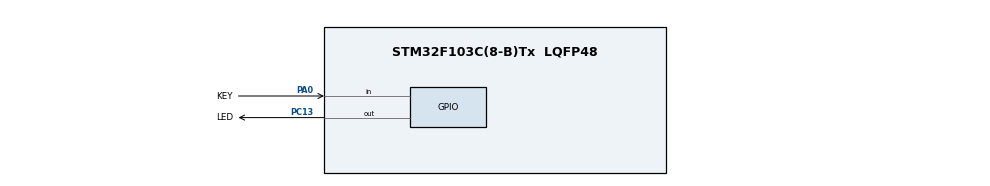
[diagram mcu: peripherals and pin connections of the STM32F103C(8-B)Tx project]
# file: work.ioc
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Mcu.Family=STM32F1
Mcu.Name=STM32F103C(8-B)Tx
Mcu.Package=LQFP48
NVIC.PriorityGroup=NVIC_PRIORITYGROUP_4
PA0-WKUP.GPIO_Label=KEY
PA0-WKUP.GPIO_PuPd=GPIO_PULLUP
PA0-WKUP.Signal=GPIO_Input
PA13.Mode=Serial_Wire
PA13.Signal=SYS_JTMS-SWDIO
PA14.Mode=Serial_Wire
PA14.Signal=SYS_JTCK-SWCLK
PC13-TAMPER-RTC.GPIO_Label=LED
PC13-TAMPER-RTC.GPIO_PuPd=GPIO_PULLUP
PC13-TAMPER-RTC.Signal=GPIO_Output
ProjectManager.HeapSize=0x200
ProjectManager.StackSize=0x400
ProjectManager.TargetToolchain=STM32CubeIDE
RCC.APB1Freq_Value=8000000
RCC.APB2Freq_Value=8000000
board=custom

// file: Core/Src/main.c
/* USER CODE BEGIN Header */
/**
  ******************************************************************************
  * @file           : main.c
  * @brief          : Main program body
  ******************************************************************************
  * @attention
  *
  * Copyright (c) 2026 STMicroelectronics.
  * All rights reserved.
  *
  * This software is licensed under terms that can be found in the LICENSE file
  * in the root directory of this software component.
  * If no LICENSE file comes with this software, it is provided AS-IS.
  *
  ******************************************************************************
  */
/* USER CODE END Header */

#include "main.h"

/* USER CODE BEGIN PD */

/* 自定义引脚宏定义 */
#define LED_Pin     GPIO_PIN_13
#define LED_Port    GPIOC
#define KEY_Pin     GPIO_PIN_0
#define KEY_Port    GPIOA

/* 简化操作宏 */
#define LED_ON()    HAL_GPIO_WritePin(LED_Port, LED_Pin, GPIO_PIN_RESET)   /* 低电平点亮 */
#define LED_OFF()   HAL_GPIO_WritePin(LED_Port, LED_Pin, GPIO_PIN_SET)     /* 高电平熄灭 */
#define LED_TOGGLE() HAL_GPIO_TogglePin(LED_Port, LED_Pin)
#define KEY_PRESSED() (HAL_GPIO_ReadPin(KEY_Port, KEY_Pin) == GPIO_PIN_RESET)  /* 按键按下=低电平 */

/* USER CODE END PD */

void SystemClock_Config(void);
static void MX_GPIO_Init(void);
static uint8_t Key_Scan(void);   /* 按键扫描函数声明 */

int main(void)
{

    /* MCU Configuration--------------------------------------------------------*/
    /* Reset of all peripherals, Initializes the Flash interface and the Systick. */
    HAL_Init();

    /* Configure the system clock */
    SystemClock_Config();

    /* Initialize all configured peripherals */
    MX_GPIO_Init();

    /* Infinite loop */
    /* USER CODE BEGIN WHILE */
    while (1)
    {
        /* 最简单的按键检测：按下时 LED 亮，松开时 LED 灭 */
        if (HAL_GPIO_ReadPin(GPIOA, GPIO_PIN_0) == GPIO_PIN_RESET)  // 按键按下
        {
            HAL_GPIO_WritePin(GPIOC, GPIO_PIN_13, GPIO_PIN_RESET);  // LED 亮
        }
        else
        {
            HAL_GPIO_WritePin(GPIOC, GPIO_PIN_13, GPIO_PIN_SET);    // LED 灭
        }
    }
    /* USER CODE END 3 */
}

void SystemClock_Config(void)
{
    RCC_OscInitTypeDef RCC_OscInitStruct = {0};
    RCC_ClkInitTypeDef RCC_ClkInitStruct = {0};

    /* 配置 HSI 作为系统时钟（不需要外部晶振）*/
    RCC_OscInitStruct.OscillatorType = RCC_OSCILLATORTYPE_HSI;
    RCC_OscInitStruct.HSIState = RCC_HSI_ON;
    RCC_OscInitStruct.HSICalibrationValue = RCC_HSICALIBRATION_DEFAULT;
    RCC_OscInitStruct.PLL.PLLState = RCC_PLL_NONE;
    if (HAL_RCC_OscConfig(&RCC_OscInitStruct) != HAL_OK)
    {
        Error_Handler();
    }

    /* 配置时钟分频 */
    RCC_ClkInitStruct.ClockType = RCC_CLOCKTYPE_HCLK | RCC_CLOCKTYPE_SYSCLK
                                  | RCC_CLOCKTYPE_PCLK1 | RCC_CLOCKTYPE_PCLK2;
    RCC_ClkInitStruct.SYSCLKSource = RCC_SYSCLKSOURCE_HSI;
    RCC_ClkInitStruct.AHBCLKDivider = RCC_SYSCLK_DIV1;
    RCC_ClkInitStruct.APB1CLKDivider = RCC_HCLK_DIV1;
    RCC_ClkInitStruct.APB2CLKDivider = RCC_HCLK_DIV1;

    if (HAL_RCC_ClockConfig(&RCC_ClkInitStruct, FLASH_LATENCY_0) != HAL_OK)
    {
        Error_Handler();
    }
}

static void MX_GPIO_Init(void)
{
    GPIO_InitTypeDef GPIO_InitStruct = {0};

    /* GPIO Ports Clock Enable */
    __HAL_RCC_GPIOC_CLK_ENABLE();   /* PC 端口时钟 */
    __HAL_RCC_GPIOA_CLK_ENABLE();   /* PA 端口时钟 */

    /* 设置 LED(PC13) 初始电平：高电平（LED 熄灭）*/
    HAL_GPIO_WritePin(LED_Port, LED_Pin, GPIO_PIN_SET);

    /* 配置 LED 引脚：PC13 推挽输出 */
    GPIO_InitStruct.Pin = LED_Pin;
    GPIO_InitStruct.Mode = GPIO_MODE_OUTPUT_PP;
    GPIO_InitStruct.Pull = GPIO_NOPULL;       /* 输出模式不需要上拉/下拉 */
    GPIO_InitStruct.Speed = GPIO_SPEED_FREQ_LOW;
    HAL_GPIO_Init(LED_Port, &GPIO_InitStruct);

    /* 配置 KEY 引脚：PA0 上拉输入 */
    GPIO_InitStruct.Pin = KEY_Pin;
    GPIO_InitStruct.Mode = GPIO_MODE_INPUT;
    GPIO_InitStruct.Pull = GPIO_PULLUP;       /* 上拉输入，默认高电平 */
    HAL_GPIO_Init(KEY_Port, &GPIO_InitStruct);

}

/**
  * @brief  带状态机消抖的按键扫描函数
  * @retval 1: 有效按键按下  0: 无按键或抖动
  */
static uint8_t Key_Scan(void)
{
    static uint8_t key_state = 0;      /* 0:等待按键, 1:消抖确认, 2:等待释放 */
    static uint32_t debounce_time = 0;

    switch(key_state)
    {
        case 0:  /* 等待按键按下 */
            if(KEY_PRESSED())
            {
                key_state = 1;
                debounce_time = HAL_GetTick();
            }
            break;

        case 1:  /* 消抖延时确认 */
            if(KEY_PRESSED() && (HAL_GetTick() - debounce_time >= 20))
            {
                key_state = 2;
                return 1;              /* 有效按键按下 */
            }
            else if(!KEY_PRESSED())
            {
                key_state = 0;         /* 抖动，回到等待状态 */
            }
            break;

        case 2:  /* 等待按键释放 */
            if(!KEY_PRESSED())
            {
                key_state = 0;         /* 按键已释放，回到等待 */
            }
            break;
    }

    return 0;   /* 无有效按键 */
}

void Error_Handler(void)
{
    __disable_irq();
    while (1)
    {
    }
}
